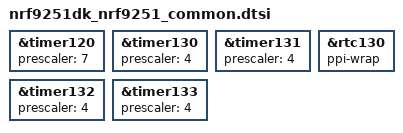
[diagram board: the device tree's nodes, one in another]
&timer120 {
	status = "okay";
	prescaler = <7>;
};

&timer130 {
	status = "okay";
	prescaler = <4>;
};

&timer131 {
	status = "okay";
	prescaler = <4>;
};

&timer132 {
	status = "okay";
	prescaler = <4>;
};

&timer133 {
	status = "okay";
	prescaler = <4>;
};

&rtc130 {
	status = "okay";
	ppi-wrap;
};
